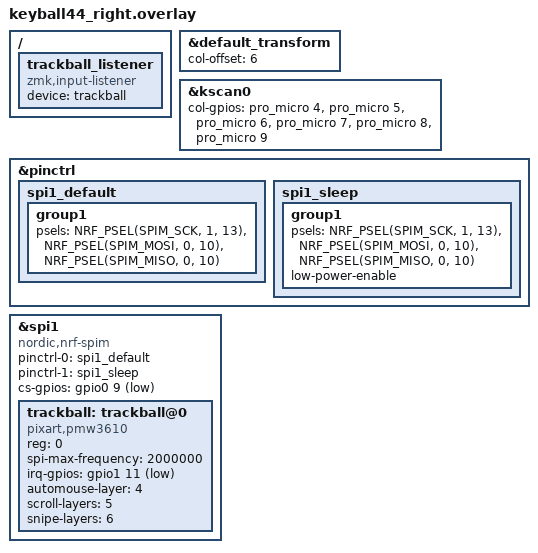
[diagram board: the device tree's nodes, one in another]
/*
 * Copyright (c) 2020 ZMK Contributors
 *
 * SPDX-License-Identifier: MIT
 */

/* Keyball44 の基本設定をインクルード */
#include "keyball44.dtsi"

/* キーマップ変換設定（右側用：列オフセット6） */
&default_transform {
    col-offset = <6>;
};

/* キースキャン用GPIO設定 */
&kscan0 {
    col-gpios = <&pro_micro 4 GPIO_ACTIVE_HIGH>,
                <&pro_micro 5 GPIO_ACTIVE_HIGH>,
                <&pro_micro 6 GPIO_ACTIVE_HIGH>,
                <&pro_micro 7 GPIO_ACTIVE_HIGH>,
                <&pro_micro 8 GPIO_ACTIVE_HIGH>,
                <&pro_micro 9 GPIO_ACTIVE_HIGH>;
};

/* SPI用のピン制御グループの定義 */
&pinctrl {
    spi1_default: spi1_default {
        group1 {
            psels = <NRF_PSEL(SPIM_SCK, 1, 13)>,
                    <NRF_PSEL(SPIM_MOSI, 0, 10)>,
                    <NRF_PSEL(SPIM_MISO, 0, 10)>;
        };
    };

    spi1_sleep: spi1_sleep {
        group1 {
            psels = <NRF_PSEL(SPIM_SCK, 1, 13)>,
                    <NRF_PSEL(SPIM_MOSI, 0, 10)>,
                    <NRF_PSEL(SPIM_MISO, 0, 10)>;
            low-power-enable;
        };
    };
};

/* SPIバスおよびトラックボールセンサーの定義 */
&spi1 {
    status = "okay";
    compatible = "nordic,nrf-spim";
    pinctrl-0 = <&spi1_default>;
    pinctrl-1 = <&spi1_sleep>;
    pinctrl-names = "default", "sleep";
    cs-gpios = <&gpio0 9 GPIO_ACTIVE_LOW>;

    trackball: trackball@0 {
        status = "okay";
        compatible = "pixart,pmw3610";  /* ※ 現在 "pixart,pmw3610" となっていますが、
                                           ご使用のセンサーはPMW3610DMの場合、ドライバが両者を共通扱いするか、
                                           もしくは "pixart,pmw3610dm" とする必要があるか検討してください。 */
        reg = <0>;
        spi-max-frequency = <2000000>;
        irq-gpios = <&gpio1 11 (GPIO_ACTIVE_LOW | GPIO_PULL_UP)>;
        automouse-layer = <4>;
        scroll-layers = <5>;
        snipe-layers = <6>;
    };
};

/* トラックボール入力リスナーの定義（ルートノードに配置） */
 / {
    trackball_listener {
        compatible = "zmk,input-listener";
        device = <&trackball>;
    };
};
